# RL6845_IP_SVD register map
Vendor: Realtek
Registers are 32-bit, read-write, reset 0x0 unless marked. A register's access mark holds for its fields unless they carry their own. Offsets are from the block's base; [hi:lo] are bit positions; {n}, {i} and the like mark numbered series.

## otpc_sec
Base 0x41000000
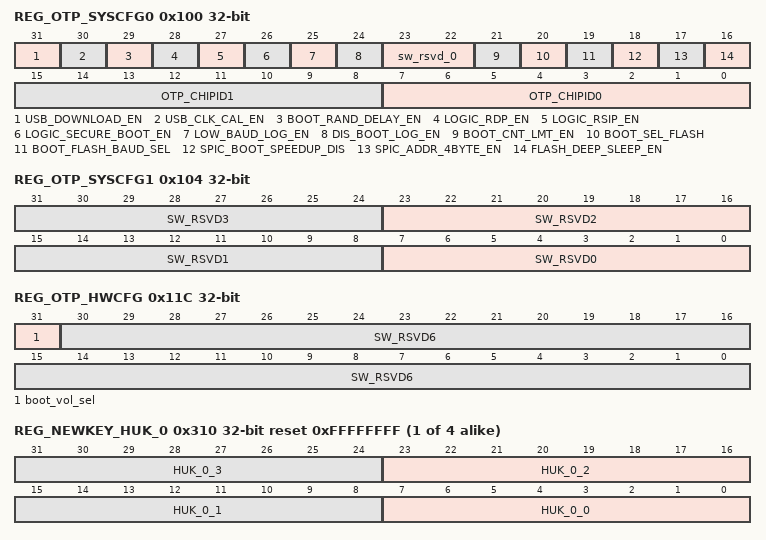
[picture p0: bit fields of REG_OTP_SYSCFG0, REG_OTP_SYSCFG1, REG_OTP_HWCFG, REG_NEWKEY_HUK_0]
0x100 REG_OTP_SYSCFG0
  [31] USB_DOWNLOAD_EN — USB download enable 0: disable 1: enable
  [30] USB_CLK_CAL_EN — SoC clock calibration for USB 0: disable 1: enable
  [29] BOOT_RAND_DELAY_EN — Enable random boot delay 0: disable 1: enable
  [28] LOGIC_RDP_EN — RDP enable
  [27] LOGIC_RSIP_EN — RSIP enable
  [26] LOGIC_SECURE_BOOT_EN — Secure boot enable
  [25] LOW_BAUD_LOG_EN — Loguart Baudrate selection 1: 115200bps 0: 1.5Mbps
  [24] DIS_BOOT_LOG_EN — Boot log disable
  [23:22] sw_rsvd_0 — Reserved for SW usage
  [21] BOOT_CNT_LMT_EN — Enable boot count limit 0: disable 1: enable
  [20] BOOT_SEL_FLASH — Boot select. Boot from internal flash or external flash. 0'b0: internal flash 0'b1: external flash
  [19] BOOT_FLASH_BAUD_SEL — Boot Flash clock selection. Baudrate = 40/(2*(1+x)) 0: 20M 1: 10M
  [18] SPIC_BOOT_SPEEDUP_DIS — SPIC boot speed up disable
  [17] SPIC_ADDR_4BYTE_EN — SPIC address 4-byte enable
  [16] FLASH_DEEP_SLEEP_EN — Flash deepsleep enable
  [15:8] OTP_CHIPID1 — OTP autuload data reserved for SW
  [7:0] OTP_CHIPID0 — OTP autuload data reserved for SW
0x104 REG_OTP_SYSCFG1
  [8n+7:8n] SW_RSVD{n} (n=0..3) — RSVD for SW usage
0x108 REG_OTP_SYSCFG2
  [31:0] SW_RSVD4 — RSVD for SW usage
0x10C REG_OTP_SYSCFG3
  [31:0] SW_RSVD5 — RSVD for SW usage
0x11C REG_OTP_HWCFG
  [31] boot_vol_sel — BOOT Voltage Selection: 0'b0: 0.9V 0'b1: 1.0V
  [30:0] SW_RSVD6 — RSVD for SW usage
{0x200+4i} REG_KEY_S_IPSEC1_{i} ro reset 0xFFFFFFFF (i=0..7)
  [31:0] key_S_IPSEC1_{i}
{0x220+4i} REG_KEY_S_IPSEC2_{i} ro reset 0xFFFFFFFF (i=0..7)
  [31:0] key_S_IPSEC2_{i}
{0x240+4i} REG_KEY_NS_IPSEC1_{i} ro reset 0xFFFFFFFF (i=0..7)
  [31:0] key_NS_IPSEC1_{i}
{0x260+4i} REG_KEY_NS_IPSEC2_{i} ro reset 0xFFFFFFFF (i=0..7)
  [31:0] key_NS_IPSEC2_{i}
{0x2C0+4i} REG_KEY_RSIP_ECB_{i} ro reset 0xFFFFFFFF (i=0..7)
  [31:0] key_RSIP_ECB_{i}
{0x2E0+4i} REG_KEY_RSIP_CTR_{i} ro reset 0xFFFFFFFF (i=0..7)
  [31:0] key_RSIP_CTR_{i}
{0x300+4i} REG_KEY_SWD_PWD_{i} ro reset 0xFFFFFFFF (i=0..3)
  [31:0] key_SWD_PWD_{i}
{0x310+4i} REG_NEWKEY_HUK_{i} ro reset 0xFFFFFFFF (i=0..3)
  [8n+7:8n] HUK_{i}_{n} (n=0..3)
{0x320+4i} REG_PKKEY_PK1_{i} ro reset 0xFFFFFFFF (i=0..7)
  [31:0] key_PK1_{i}
{0x340+4i} REG_PKKEY_PK2_{i} ro reset 0xFFFFFFFF (i=0..7)
  [31:0] key_PK2_{i}
0x360 REG_SEC_CFG0 ro reset 0xFFFFFFFF
  [31:0] swd_id
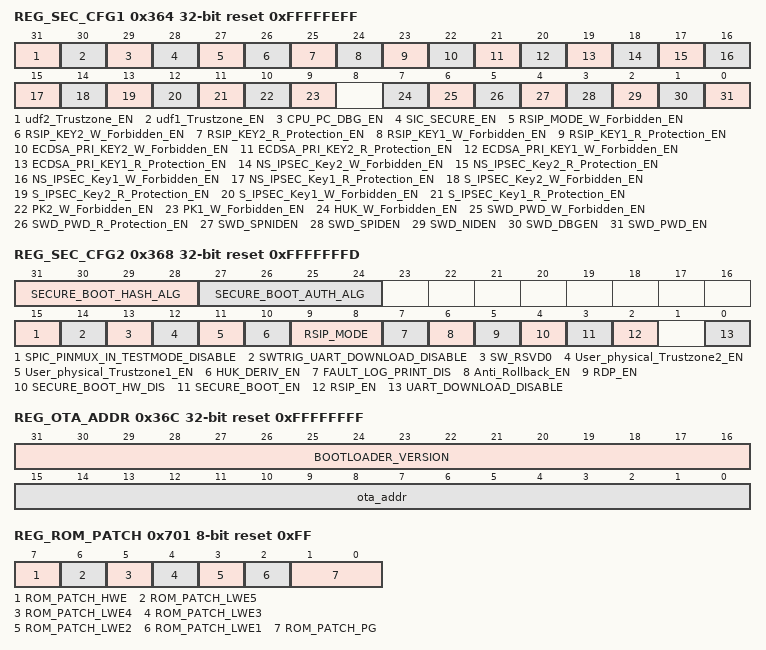
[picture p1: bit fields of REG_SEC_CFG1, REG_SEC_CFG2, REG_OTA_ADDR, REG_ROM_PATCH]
0x364 REG_SEC_CFG1 ro reset 0xFFFFFEFF
  [31] udf2_Trustzone_EN, [30] udf1_Trustzone_EN, [29] CPU_PC_DBG_EN, [28] SIC_SECURE_EN, [27] RSIP_MODE_W_Forbidden_EN, [26] RSIP_KEY2_W_Forbidden_EN, [25] RSIP_KEY2_R_Protection_EN, [24] RSIP_KEY1_W_Forbidden_EN, [23] RSIP_KEY1_R_Protection_EN, [22] ECDSA_PRI_KEY2_W_Forbidden_EN, [21] ECDSA_PRI_KEY2_R_Protection_EN, [20] ECDSA_PRI_KEY1_W_Forbidden_EN, [19] ECDSA_PRI_KEY1_R_Protection_EN, [18] NS_IPSEC_Key2_W_Forbidden_EN, [17] NS_IPSEC_Key2_R_Protection_EN, [16] NS_IPSEC_Key1_W_Forbidden_EN, [15] NS_IPSEC_Key1_R_Protection_EN, [14] S_IPSEC_Key2_W_Forbidden_EN, [13] S_IPSEC_Key2_R_Protection_EN, [12] S_IPSEC_Key1_W_Forbidden_EN, [11] S_IPSEC_Key1_R_Protection_EN, [10] PK2_W_Forbidden_EN, [9] PK1_W_Forbidden_EN, [7] HUK_W_Forbidden_EN, [6] SWD_PWD_W_Forbidden_EN, [5] SWD_PWD_R_Protection_EN, [4] SWD_SPNIDEN, [3] SWD_SPIDEN, [2] SWD_NIDEN, [1] SWD_DBGEN, [0] SWD_PWD_EN
0x368 REG_SEC_CFG2 ro reset 0xFFFFFFFD
  [31:28] SECURE_BOOT_HASH_ALG, [27:24] SECURE_BOOT_AUTH_ALG, [15] SPIC_PINMUX_IN_TESTMODE_DISABLE, [14] SWTRIG_UART_DOWNLOAD_DISABLE, [13] SW_RSVD0, [12] User_physical_Trustzone2_EN, [11] User_physical_Trustzone1_EN, [10] HUK_DERIV_EN, [9:8] RSIP_MODE, [7] FAULT_LOG_PRINT_DIS, [6] Anti_Rollback_EN, [5] RDP_EN, [4] SECURE_BOOT_HW_DIS, [3] SECURE_BOOT_EN, [2] RSIP_EN, [0] UART_DOWNLOAD_DISABLE
0x36C REG_OTA_ADDR ro reset 0xFFFFFFFF
  [31:16] BOOTLOADER_VERSION, [15:0] ota_addr
0x370 REG_CRC0 ro reset 0xFFFFFFFF
  [31:0] crc_entry0 — [15:0] : magic data [31:16]: valid crc Note : this field will be autoload twice time, and stick to L
{0x370+4i} REG_CRC{i} ro reset 0xFFFFFFFF (i=1..3)
  [31:0] crc_entry{i}
0x700 REG_RMA 8-bit ro reset 0xFF
  [7:0] RMA_DATA — If the number of 1 is odd, it will goto RMA state.
0x701 REG_ROM_PATCH 8-bit ro reset 0xFF
  [7] ROM_PATCH_HWE — ROM patch write protection (protect High 2Kbits)
  [6] ROM_PATCH_LWE5 — ROM patch write protection(protect low 1Kbits) :580-5ff
  [5] ROM_PATCH_LWE4 — ROM patch write protection(protect Low 256bits): 560-57f
  [4] ROM_PATCH_LWE3 — ROM patch write protection(protect Low 256bits) : 540-55f
  [3] ROM_PATCH_LWE2 — ROM patch write protection(protect Low 256bits) : 520-53f
  [2] ROM_PATCH_LWE1 — ROM patch write protection(protect Low 256bits) : 500-51f
  [1:0] ROM_PATCH_PG — ROM patch enable.This Bit will programed by FT if ROM patch do not needed
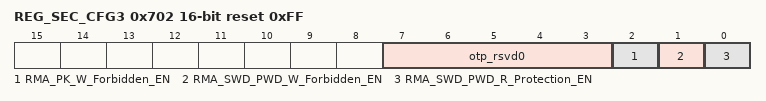
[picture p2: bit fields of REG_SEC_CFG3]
0x702 REG_SEC_CFG3 16-bit ro reset 0xFF
  [7:3] otp_rsvd0, [2] RMA_PK_W_Forbidden_EN, [1] RMA_SWD_PWD_W_Forbidden_EN, [0] RMA_SWD_PWD_R_Protection_EN
{0x710+4i} REG_SWD_RMA_PWD_{i} ro reset 0xFFFFFFFF (i=0..3)
  [31:0] key_RMA_PWD_{i}
{0x720+4i} REG_PKKEY_RMA_PK_{i} ro reset 0xFFFFFFFF (i=0..7)
  [31:0] key_RMA_PK_{i}
0x740 OTP_DUMMY
  [7:0] dummy — dummy reg for hw
